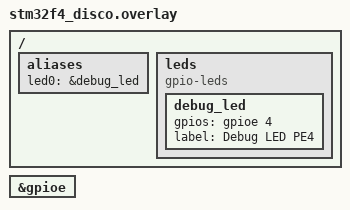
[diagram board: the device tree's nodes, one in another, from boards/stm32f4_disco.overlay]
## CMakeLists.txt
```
cmake_minimum_required(VERSION 3.20.0)
find_package(Zephyr REQUIRED HINTS $ENV{ZEPHYR_BASE})
project(stm32_pe4_blink)
target_sources(app PRIVATE src/main.c)
```

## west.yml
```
manifest:
  version: "0.13"
  remotes:
    - name: zephyrproject
      url-base: https://github.com/zephyrproject-rtos
  projects:
    - name: zephyr
      remote: zephyrproject
      revision: v4.3.0
      import: true
  self:
    path: app
```

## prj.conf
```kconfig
CONFIG_GPIO=y
CONFIG_CONSOLE=y
CONFIG_PRINTK=y
CONFIG_DEBUG=y
```

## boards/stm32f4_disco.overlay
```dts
#include <zephyr/dt-bindings/gpio/gpio.h>

/ {
    aliases {
        led0 = &debug_led;
    };

    /* Extend the existing stm32f4_disco 'leds' node. */
    leds {
        compatible = "gpio-leds";

        debug_led: debug_led {
            gpios = <&gpioe 4 GPIO_ACTIVE_HIGH>;
            label = "Debug LED PE4";
        };
    };
};

&gpioe {
    status = "okay";
};
```

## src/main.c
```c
#include <zephyr/kernel.h>
#include <zephyr/drivers/gpio.h>
#include <zephyr/sys/printk.h>

#define LED_NODE DT_ALIAS(led0)

#if !DT_NODE_EXISTS(LED_NODE)
#error "No led0 alias defined in devicetree"
#endif

static const struct gpio_dt_spec led = GPIO_DT_SPEC_GET(LED_NODE, gpios);

int main(void)
{
    int ret;

    if (!gpio_is_ready_dt(&led)) {
        printk("LED GPIO controller is not ready\n");
        return 0;
    }

    ret = gpio_pin_configure_dt(&led, GPIO_OUTPUT_INACTIVE);
    if (ret < 0) {
        printk("Failed to configure LED: %d\n", ret);
        return 0;
    }

    printk("Zephyr STM32F4 Discovery: toggling LED on PE4\n");

    while (1) {
        ret = gpio_pin_toggle_dt(&led);
        if (ret < 0) {
            printk("Failed to toggle LED: %d\n", ret);
        }
        k_msleep(500);
    }

    return 0;
}
```
